# STM32F746xx register map
File version: 1.0
Registers are 32-bit, read-write, reset 0x0 unless marked. A register's access mark holds for its fields unless they carry their own. Offsets are from the block's base; [hi:lo] are bit positions; {n}, {i} and the like mark numbered series.

## SPI2 — Serial Peripheral Interface
Base 0x40003800
Same registers: SPI3 0x40003C00, SPI1 0x40013000, SPI4 0x40013400, SPI5 0x40015000, SPI6 0x40015400
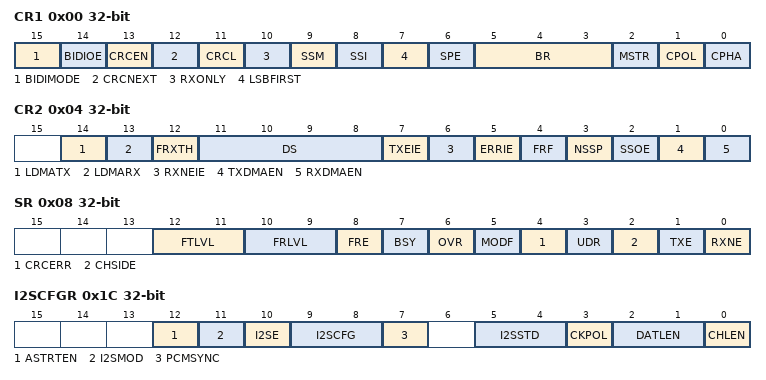
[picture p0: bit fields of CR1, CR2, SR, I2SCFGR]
0x00 CR1 — SPI control register 1 (not used in I2S mode)
  [15] BIDIMODE — Bidirectional data mode enable
  [14] BIDIOE — Output enable in bidirectional mode
  [13] CRCEN — Hardware CRC calculation enable
  [12] CRCNEXT — Transmit CRC next
  [11] CRCL — CRC Length
    0=CRC_8BIT (8-bit CRC length); 1=CRC_16BIT (16-bit CRC length)
  [10] RXONLY — Receive only
  [9] SSM — Software slave management
  [8] SSI — Internal slave select
  [7] LSBFIRST — Frame Format
    1=LSB_FIRST (Data is transmitted/received with the LSB first); 0=MSB_FIRST (Data is transmitted/received with the MSB first)
  [6] SPE — SPI Enable
  [5:3] BR — BR[2:0] bits (Baud Rate Control)
    0=DIV2 (BaudRate control equal to fPCLK/2); 1=DIV4 (BaudRate control equal to fPCLK/4); 2=DIV8 (BaudRate control equal to fPCLK/8); 3=DIV16 (BaudRate control equal to fPCLK/16); 4=DIV32 (BaudRate control equal to fPCLK/32); 5=DIV64 (BaudRate control equal to fPCLK/64); 6=DIV128 (BaudRate control equal to fPCLK/128); 7=DIV256 (BaudRate control equal to fPCLK/256)
  [2] MSTR — Master Selection
  [1] CPOL — Clock Polarity
    0=LOW (Clock to 0 when idle); 1=HIGH (Clock to 1 when idle)
  [0] CPHA — Clock Phase
    0=PHASE_1EDGE (First clock transition is the first data capture edge); 1=PHASE_2EDGE (Second clock transition is the first data capture edge)
0x04 CR2 — SPI control register 2
  [14] LDMATX — Last DMA transfer for transmission
  [13] LDMARX — Last DMA transfer for reception
  [12] FRXTH — FIFO reception Threshold
    0=HALF (RXNE event is generated if FIFO level is greater than or equal to 1/2 (16-bit)); 1=QUARTER (RXNE event is generated if FIFO level is greater than or equal to 1/4 (8-bit))
  [11:8] DS — DS[3:0] Data Size
    {v}=DATAWIDTH_{v+1}BIT (Data length for SPI transfer: {v+1} bits) (v=3..15)
  [7] TXEIE — Tx buffer Empty Interrupt Enable
  [6] RXNEIE — RX buffer Not Empty Interrupt Enable
  [5] ERRIE — Error Interrupt Enable
  [4] FRF — Frame Format Enable
    0=MOTOROLA (Motorola mode. Used as default value); 1=TI (TI mode)
  [3] NSSP — NSS pulse management Enable
  [2] SSOE — SS Output Enable
  [1] TXDMAEN — Tx Buffer DMA Enable
  [0] RXDMAEN — Rx Buffer DMA Enable
0x08 SR — SPI status register
  [12:11] FTLVL — FIFO Transmission Level
    0=EMPTY (FIFO transmission empty); 1=QUARTER_FULL (FIFO transmission 1/4); 2=HALF_FULL (FIFO transmission 1/2); 3=FULL (FIFO transmission full)
  [10:9] FRLVL — FIFO Reception Level
    0=EMPTY (FIFO reception empty); 1=QUARTER_FULL (FIFO reception 1/4); 2=HALF_FULL (FIFO reception 1/2); 3=FULL (FIFO reception full)
  [8] FRE — TI frame format error
  [7] BSY — Busy flag
  [6] OVR — Overrun flag
  [5] MODF — Mode fault
  [4] CRCERR — CRC Error flag
  [3] UDR — Underrun flag
  [2] CHSIDE — Channel side
  [1] TXE — Transmit buffer Empty
  [0] RXNE — Receive buffer Not Empty
0x0C DR — SPI data register
  [15:0] DR — Data Register
0x10 CRCPR — SPI CRC polynomial register (not used in I2S mode)
  [15:0] CRCPOLY — CRC polynomial register
0x14 RXCRCR — SPI RX CRC register (not used in I2S mode)
  [15:0] RXCRC
0x18 TXCRCR — SPI TX CRC register (not used in I2S mode)
  [15:0] TXCRC
0x1C I2SCFGR — SPI_I2S configuration register
  [12] ASTRTEN — Asynchronous start enable
  [11] I2SMOD — I2S mode selection
  [10] I2SE — I2S Enable
  [9:8] I2SCFG — I2SCFG[1:0] bits (I2S configuration mode)
    0=SLAVE_TX (Slave Tx configuration); 1=SLAVE_RX (Slave Rx configuration); 2=MASTER_TX (Master Tx configuration); 3=MASTER_RX (Master Rx configuration)
  [7] PCMSYNC — PCM frame synchronization
  [5:4] I2SSTD — I2SSTD[1:0] bits (I2S standard selection)
  [3] CKPOL — steady state clock polarity
    0=LOW (Clock steady state is low level); 1=HIGH (Clock steady state is high level)
  [2:1] DATLEN — DATLEN[1:0] bits (Data length to be transferred)
  [0] CHLEN — Channel length (number of bits per audio channel)
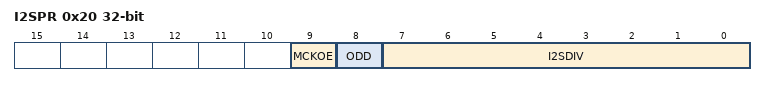
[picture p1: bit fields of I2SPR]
0x20 I2SPR — SPI_I2S prescaler register
  [9] MCKOE — Master Clock Output Enable
  [8] ODD — Odd factor for the prescaler
  [7:0] I2SDIV — I2S Linear prescaler
